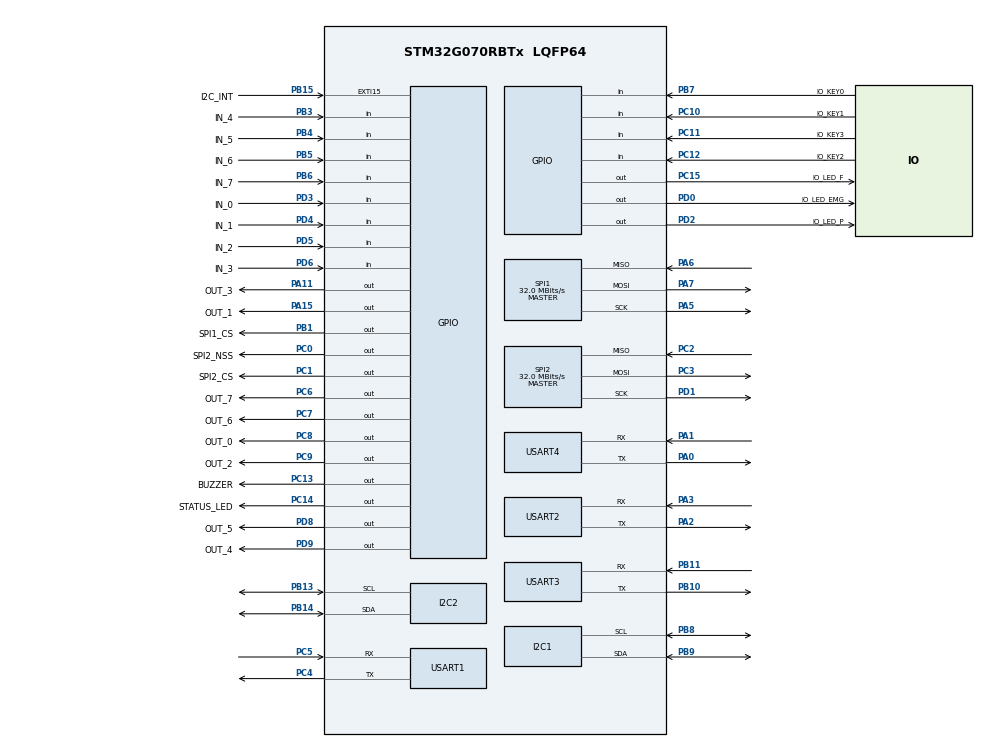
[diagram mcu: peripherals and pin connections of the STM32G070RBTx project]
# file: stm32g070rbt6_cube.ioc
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Dma.Request0=USART1_RX
Dma.Request1=USART1_TX
Dma.Request2=USART3_RX
Dma.Request3=USART3_TX
Dma.USART1_RX.0.Direction=DMA_PERIPH_TO_MEMORY
Dma.USART1_RX.0.EventEnable=DISABLE
Dma.USART1_RX.0.Instance=DMA1_Channel1
Dma.USART1_RX.0.MemDataAlignment=DMA_MDATAALIGN_BYTE
Dma.USART1_RX.0.MemInc=DMA_MINC_ENABLE
Dma.USART1_RX.0.Mode=DMA_CIRCULAR
Dma.USART1_RX.0.PeriphDataAlignment=DMA_PDATAALIGN_BYTE
Dma.USART1_RX.0.PeriphInc=DMA_PINC_DISABLE
Dma.USART1_RX.0.Polarity=HAL_DMAMUX_REQ_GEN_RISING
Dma.USART1_RX.0.Priority=DMA_PRIORITY_LOW
Dma.USART1_RX.0.RequestNumber=1
Dma.USART1_RX.0.SignalID=NONE
Dma.USART1_RX.0.SyncEnable=DISABLE
Dma.USART1_RX.0.SyncPolarity=HAL_DMAMUX_SYNC_NO_EVENT
Dma.USART1_RX.0.SyncRequestNumber=1
Dma.USART1_RX.0.SyncSignalID=NONE
Dma.USART1_TX.1.Direction=DMA_MEMORY_TO_PERIPH
Dma.USART1_TX.1.EventEnable=DISABLE
Dma.USART1_TX.1.Instance=DMA1_Channel2
Dma.USART1_TX.1.MemDataAlignment=DMA_MDATAALIGN_BYTE
Dma.USART1_TX.1.MemInc=DMA_MINC_ENABLE
Dma.USART1_TX.1.Mode=DMA_NORMAL
Dma.USART1_TX.1.PeriphDataAlignment=DMA_PDATAALIGN_BYTE
Dma.USART1_TX.1.PeriphInc=DMA_PINC_DISABLE
Dma.USART1_TX.1.Polarity=HAL_DMAMUX_REQ_GEN_RISING
Dma.USART1_TX.1.Priority=DMA_PRIORITY_LOW
Dma.USART1_TX.1.RequestNumber=1
Dma.USART1_TX.1.SignalID=NONE
Dma.USART1_TX.1.SyncEnable=DISABLE
Dma.USART1_TX.1.SyncPolarity=HAL_DMAMUX_SYNC_NO_EVENT
Dma.USART1_TX.1.SyncRequestNumber=1
Dma.USART1_TX.1.SyncSignalID=NONE
Dma.USART3_RX.2.Direction=DMA_PERIPH_TO_MEMORY
Dma.USART3_RX.2.EventEnable=DISABLE
Dma.USART3_RX.2.Instance=DMA1_Channel3
Dma.USART3_RX.2.MemDataAlignment=DMA_MDATAALIGN_BYTE
Dma.USART3_RX.2.MemInc=DMA_MINC_ENABLE
Dma.USART3_RX.2.Mode=DMA_CIRCULAR
Dma.USART3_RX.2.PeriphDataAlignment=DMA_PDATAALIGN_BYTE
Dma.USART3_RX.2.PeriphInc=DMA_PINC_DISABLE
Dma.USART3_RX.2.Polarity=HAL_DMAMUX_REQ_GEN_RISING
Dma.USART3_RX.2.Priority=DMA_PRIORITY_LOW
Dma.USART3_RX.2.RequestNumber=1
Dma.USART3_RX.2.SignalID=NONE
Dma.USART3_RX.2.SyncEnable=DISABLE
Dma.USART3_RX.2.SyncPolarity=HAL_DMAMUX_SYNC_NO_EVENT
Dma.USART3_RX.2.SyncRequestNumber=1
Dma.USART3_RX.2.SyncSignalID=NONE
Dma.USART3_TX.3.Direction=DMA_MEMORY_TO_PERIPH
Dma.USART3_TX.3.EventEnable=DISABLE
Dma.USART3_TX.3.Instance=DMA1_Channel4
Dma.USART3_TX.3.MemDataAlignment=DMA_MDATAALIGN_BYTE
Dma.USART3_TX.3.MemInc=DMA_MINC_ENABLE
Dma.USART3_TX.3.Mode=DMA_NORMAL
Dma.USART3_TX.3.PeriphDataAlignment=DMA_PDATAALIGN_BYTE
Dma.USART3_TX.3.PeriphInc=DMA_PINC_DISABLE
Dma.USART3_TX.3.Polarity=HAL_DMAMUX_REQ_GEN_RISING
Dma.USART3_TX.3.Priority=DMA_PRIORITY_LOW
Dma.USART3_TX.3.RequestNumber=1
Dma.USART3_TX.3.SignalID=NONE
Dma.USART3_TX.3.SyncEnable=DISABLE
Dma.USART3_TX.3.SyncPolarity=HAL_DMAMUX_SYNC_NO_EVENT
Dma.USART3_TX.3.SyncRequestNumber=1
Dma.USART3_TX.3.SyncSignalID=NONE
FREERTOS.Tasks01=defaultTask,0,128,StartDefaultTask,Default,NULL,Dynamic,NULL,NULL;myTask02,-3,128,StartTask02,Default,NULL,Dynamic,NULL,NULL
FREERTOS.configUSE_NEWLIB_REENTRANT=1
I2C1.Timing=0x10707DBC
I2C2.Timing=0x10707DBC
Mcu.Family=STM32G0
Mcu.Name=STM32G070RBTx
Mcu.Package=LQFP64
NVIC.DMA1_Ch4_7_DMAMUX1_OVR_IRQn=true\:3\:0\:false\:false\:true\:true\:false\:true\:true
NVIC.DMA1_Channel1_IRQn=true\:3\:0\:false\:false\:true\:true\:false\:true\:true
NVIC.DMA1_Channel2_3_IRQn=true\:3\:0\:false\:false\:true\:true\:false\:true\:true
NVIC.EXTI4_15_IRQn=true\:3\:0\:false\:false\:true\:true\:true\:true\:true
NVIC.I2C1_IRQn=true\:3\:0\:false\:false\:true\:true\:true\:true\:true
NVIC.I2C2_IRQn=true\:3\:0\:false\:false\:true\:true\:true\:true\:true
NVIC.TIM6_IRQn=true\:3\:0\:false\:false\:true\:false\:false\:true\:true
NVIC.TimeBase=TIM6_IRQn
NVIC.TimeBaseIP=TIM6
NVIC.USART2_IRQn=true\:3\:0\:false\:false\:true\:true\:true\:true\:true
PA0.Mode=Asynchronous
PA0.Signal=USART4_TX
PA1.Mode=Asynchronous
PA1.Signal=USART4_RX
PA11\ [PA9].GPIO_Label=OUT_3
PA11\ [PA9].Signal=GPIO_Output
PA13.Mode=Serial_Wire
PA13.Signal=SYS_SWDIO
PA14-BOOT0.Mode=Serial_Wire
PA14-BOOT0.Signal=SYS_SWCLK
PA15.GPIO_Label=OUT_1
PA15.Signal=GPIO_Output
PA2.Mode=Asynchronous
PA2.Signal=USART2_TX
PA3.Mode=Asynchronous
PA3.Signal=USART2_RX
PA5.Mode=Full_Duplex_Master
PA5.Signal=SPI1_SCK
PA6.Mode=Full_Duplex_Master
PA6.Signal=SPI1_MISO
PA7.Mode=Full_Duplex_Master
PA7.Signal=SPI1_MOSI
PB0.Signal=SPI1_NSS
PB1.GPIO_Label=SPI1_CS
PB1.Signal=GPIO_Output
PB10.Mode=Asynchronous
PB10.Signal=USART3_TX
PB11.Mode=Asynchronous
PB11.Signal=USART3_RX
PB13.Mode=I2C
PB13.Signal=I2C2_SCL
PB14.Mode=I2C
PB14.Signal=I2C2_SDA
PB15.GPIO_Label=I2C_INT
PB15.Signal=GPXTI15
PB3.GPIO_Label=IN_4
PB3.Signal=GPIO_Input
PB4.GPIO_Label=IN_5
PB4.Signal=GPIO_Input
PB5.GPIO_Label=IN_6
PB5.Signal=GPIO_Input
PB6.GPIO_Label=IN_7
PB6.Signal=GPIO_Input
PB7.GPIO_Label=IO_KEY0
PB7.Signal=GPIO_Input
PB8.Mode=I2C
PB8.Signal=I2C1_SCL
PB9.Mode=I2C
PB9.Signal=I2C1_SDA
PC0.GPIO_Label=SPI2_NSS
PC0.Signal=GPIO_Output
PC1.GPIO_Label=SPI2_CS
PC1.Signal=GPIO_Output
PC10.GPIO_Label=IO_KEY1
PC10.Signal=GPIO_Input
PC11.GPIO_Label=IO_KEY3
PC11.Signal=GPIO_Input
PC12.GPIO_Label=IO_KEY2
PC12.Signal=GPIO_Input
PC13.GPIO_Label=BUZZER
PC13.Signal=GPIO_Output
PC14-OSC32_IN\ (PC14).GPIO_Label=STATUS_LED
PC14-OSC32_IN\ (PC14).Signal=GPIO_Output
PC15-OSC32_OUT\ (PC15).GPIO_Label=IO_LED_F
PC15-OSC32_OUT\ (PC15).Signal=GPIO_Output
PC2.Mode=Full_Duplex_Master
PC2.Signal=SPI2_MISO
PC3.Mode=Full_Duplex_Master
PC3.Signal=SPI2_MOSI
PC4.Mode=Asynchronous
PC4.Signal=USART1_TX
PC5.Mode=Asynchronous
PC5.Signal=USART1_RX
PC6.GPIO_Label=OUT_7
PC6.Signal=GPIO_Output
PC7.GPIO_Label=OUT_6
PC7.Signal=GPIO_Output
PC8.GPIO_Label=OUT_0
PC8.Signal=GPIO_Output
PC9.GPIO_Label=OUT_2
PC9.Signal=GPIO_Output
PD0.GPIO_Label=IO_LED_EMG
PD0.Signal=GPIO_Output
PD1.Mode=Full_Duplex_Master
PD1.Signal=SPI2_SCK
PD2.GPIO_Label=IO_LED_P
PD2.Signal=GPIO_Output
PD3.GPIO_Label=IN_0
PD3.Signal=GPIO_Input
PD4.GPIO_Label=IN_1
PD4.Signal=GPIO_Input
PD5.GPIO_Label=IN_2
PD5.Signal=GPIO_Input
PD6.GPIO_Label=IN_3
PD6.Signal=GPIO_Input
PD8.GPIO_Label=OUT_5
PD8.Signal=GPIO_Output
PD9.GPIO_Label=OUT_4
PD9.Signal=GPIO_Output
PF0-OSC_IN\ (PF0).Mode=HSE-External-Oscillator
PF0-OSC_IN\ (PF0).Signal=RCC_OSC_IN
PF1-OSC_OUT\ (PF1).Mode=HSE-External-Oscillator
PF1-OSC_OUT\ (PF1).Signal=RCC_OSC_OUT
ProjectManager.HeapSize=0x200
ProjectManager.StackSize=0x400
ProjectManager.TargetToolchain=STM32CubeIDE
RCC.ADCFreq_Value=64000000
RCC.AHBFreq_Value=64000000
RCC.CortexFreq_Value=64000000
RCC.EXTERNAL_CLOCK_VALUE=48000
RCC.HCLKFreq_Value=64000000
RCC.HSE_VALUE=8000000
RCC.HSI_VALUE=16000000
RCC.LSE_VALUE=32768
RCC.SYSCLKFreq_VALUE=64000000
RCC.SYSCLKSource=RCC_SYSCLKSOURCE_PLLCLK
RCC.VCOOutputFreq_Value=128000000
SPI1.CalculateBaudRate=32.0 MBits/s
SPI1.Direction=SPI_DIRECTION_2LINES
SPI1.Mode=SPI_MODE_MASTER
SPI1.VirtualType=VM_MASTER
SPI2.CalculateBaudRate=32.0 MBits/s
SPI2.Direction=SPI_DIRECTION_2LINES
SPI2.Mode=SPI_MODE_MASTER
SPI2.VirtualType=VM_MASTER
USART1.VirtualMode-Asynchronous=VM_ASYNC
USART2.VirtualMode-Asynchronous=VM_ASYNC
USART3.VirtualMode-Asynchronous=VM_ASYNC
USART4.VirtualMode-Asynchronous=VM_ASYNC
VP_FREERTOS_VS_CMSIS_V1.Mode=CMSIS_V1
VP_SYS_VS_tim6.Mode=TIM6
board=custom

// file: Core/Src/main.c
/* USER CODE BEGIN Header */
/**
  ******************************************************************************
  * @file           : main.c
  * @brief          : Main program body
  ******************************************************************************
  * @attention
  *
  * Copyright (c) 2022 STMicroelectronics.
  * All rights reserved.
  *
  * This software is licensed under terms that can be found in the LICENSE file
  * in the root directory of this software component.
  * If no LICENSE file comes with this software, it is provided AS-IS.
  *
  ******************************************************************************
  */
/* USER CODE END Header */
#include "main.h"
#include "cmsis_os.h"
#include "dma.h"
#include "i2c.h"
#include "spi.h"
#include "usart.h"
#include "gpio.h"

void SystemClock_Config(void);
void MX_FREERTOS_Init(void);

int main(void)
{

  /* MCU Configuration--------------------------------------------------------*/

  /* Reset of all peripherals, Initializes the Flash interface and the Systick. */
  HAL_Init();

  /* Configure the system clock */
  SystemClock_Config();

  /* Initialize all configured peripherals */
  MX_GPIO_Init();
  MX_DMA_Init();
  MX_I2C1_Init();
  MX_I2C2_Init();
  MX_SPI1_Init();
  MX_SPI2_Init();
  MX_USART1_UART_Init();
  MX_USART2_UART_Init();
  MX_USART3_UART_Init();
  MX_USART4_UART_Init();

  /* Call init function for freertos objects (in freertos.c) */
  MX_FREERTOS_Init();

  /* Start scheduler */
  osKernelStart();

  /* We should never get here as control is now taken by the scheduler */
  /* Infinite loop */
  while (1)
  {

    /* USER CODE BEGIN 3 */
  	HAL_GPIO_TogglePin(GPIOC, GPIO_PIN_14);
  	HAL_GPIO_TogglePin(GPIOC, GPIO_PIN_1);

#if 0
  	unsigned int ms = 1000000;
  	while(ms > 1)
  	{
  		ms--;
  	}
#else
  	HAL_Delay(1000);
#endif

  }
  /* USER CODE END 3 */
}

void SystemClock_Config(void)
{
  LL_FLASH_SetLatency(LL_FLASH_LATENCY_2);
  while(LL_FLASH_GetLatency() != LL_FLASH_LATENCY_2)
  {
  }

  /* HSI configuration and activation */
  LL_RCC_HSI_Enable();
  while(LL_RCC_HSI_IsReady() != 1)
  {
  }

  /* Main PLL configuration and activation */
  LL_RCC_PLL_ConfigDomain_SYS(LL_RCC_PLLSOURCE_HSI, LL_RCC_PLLM_DIV_1, 8, LL_RCC_PLLR_DIV_2);
  LL_RCC_PLL_Enable();
  LL_RCC_PLL_EnableDomain_SYS();
  while(LL_RCC_PLL_IsReady() != 1)
  {
  }

  /* Set AHB prescaler*/
  LL_RCC_SetAHBPrescaler(LL_RCC_SYSCLK_DIV_1);

  /* Sysclk activation on the main PLL */
  LL_RCC_SetSysClkSource(LL_RCC_SYS_CLKSOURCE_PLL);
  while(LL_RCC_GetSysClkSource() != LL_RCC_SYS_CLKSOURCE_STATUS_PLL)
  {
  }

  /* Set APB1 prescaler*/
  LL_RCC_SetAPB1Prescaler(LL_RCC_APB1_DIV_1);
  /* Update CMSIS variable (which can be updated also through SystemCoreClockUpdate function) */
  LL_SetSystemCoreClock(64000000);

   /* Update the time base */
  if (HAL_InitTick (TICK_INT_PRIORITY) != HAL_OK)
  {
    Error_Handler();
  }
}

void HAL_TIM_PeriodElapsedCallback(TIM_HandleTypeDef *htim)
{
  if (htim->Instance == TIM6) {
    HAL_IncTick();
  }
}

void Error_Handler(void)
{
  __disable_irq();
  while (1)
  {
  }
}

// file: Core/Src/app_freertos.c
/* USER CODE BEGIN Header */
/**
  ******************************************************************************
  * File Name          : app_freertos.c
  * Description        : Code for freertos applications
  ******************************************************************************
  * @attention
  *
  * Copyright (c) 2022 STMicroelectronics.
  * All rights reserved.
  *
  * This software is licensed under terms that can be found in the LICENSE file
  * in the root directory of this software component.
  * If no LICENSE file comes with this software, it is provided AS-IS.
  *
  ******************************************************************************
  */
/* USER CODE END Header */

#include "FreeRTOS.h"
#include "task.h"
#include "main.h"
#include "cmsis_os.h"

osThreadId defaultTaskHandle;
osThreadId myTask02Handle;

void StartDefaultTask(void const * argument);
void StartTask02(void const * argument);

void MX_FREERTOS_Init(void); /* (MISRA C 2004 rule 8.1) */

void MX_FREERTOS_Init(void) {

  /* Create the thread(s) */
  /* definition and creation of defaultTask */
  osThreadDef(defaultTask, StartDefaultTask, osPriorityNormal, 0, 128);
  defaultTaskHandle = osThreadCreate(osThread(defaultTask), NULL);

  /* definition and creation of myTask02 */
  osThreadDef(myTask02, StartTask02, osPriorityIdle, 0, 128);
  myTask02Handle = osThreadCreate(osThread(myTask02), NULL);

}

void StartDefaultTask(void const * argument)
{
  for(;;)
  {
    osDelay(1);
  }
}

void StartTask02(void const * argument)
{
  for(;;)
  {
    osDelay(1);
  }
}
